AUTOSAR XML (schema 00044)
package /ComponentTypes
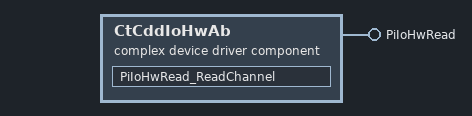
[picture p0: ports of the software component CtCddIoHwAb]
  complex device driver sw component type CtCddIoHwAb
    provide port PiIoHwRead: server-com-spec{operation=ReadChannel, queue-length=1}, provided-interface=PiIoHwRead
    behavior CtCddIoHwAb_InternalBehavior
      operation invoked event OIT_PiIoHwRead_ReadChannel_PiIoHwRead_ReadChannel: start-on-event=PiIoHwRead_ReadChannel, operation=PiIoHwRead.ReadChannel
      runnable PiIoHwRead_ReadChannel
  swc implementation CtCddIoHwAb_Implementation: behavior=CtCddIoHwAb_InternalBehavior
